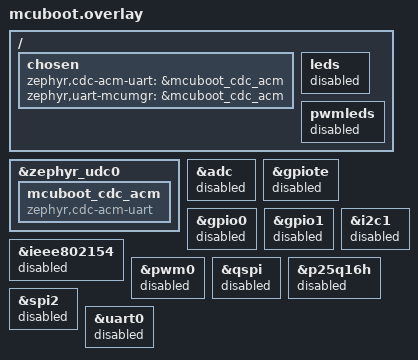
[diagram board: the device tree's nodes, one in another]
/*
 * MCUboot devicetree overlay (mcuboot sysbuild image).
 *
 * MCUboot's serial recovery runs over a USB CDC ACM UART, so a board whose
 * primary slot is empty or invalid can still be given an image over USB with
 * no SWD probe attached.
 *
 * The CDC ACM node is declared here rather than borrowed from the board. Board
 * DTS files name theirs inconsistently -- xiao_ble calls it usb_cdc_acm_uart,
 * the Adafruit nRF52840 boards call it cdc_acm_uart0 -- so referencing the
 * board's label would tie this file to one board. All this needs is
 * zephyr_udc0, which every nRF52840 has.
 */
/ {
    chosen {
        zephyr,cdc-acm-uart = &mcuboot_cdc_acm;
        zephyr,uart-mcumgr = &mcuboot_cdc_acm;
    };
};
&zephyr_udc0 {
    status = "okay";
    mcuboot_cdc_acm: mcuboot_cdc_acm {
        compatible = "zephyr,cdc-acm-uart";
    };
};

/*
 * LOCAL DEVIATION -- do not carry this to the upstream branch.
 *
 * Everything below is xiao_ble-specific and exists only to keep the bootloader
 * inside a 48 KB partition (MCUBOOT_PARTITION_SIZE = 0xC000 in __init__.py),
 * which is the size already flashed on our boards. Upstream deliberately has no
 * disable list: it is what makes the overlay board-agnostic, and it pays for
 * that with a 64 KB partition. The two go together -- restoring 0x10000 without
 * dropping this list just wastes 16 KB of slot.
 *
 * A bootloader needs USB and flash. It does not need the radio, the analog
 * front end, the external QSPI part, or any of the pin peripherals: serial
 * recovery is entered by an invalid primary slot, not by a GPIO
 * (BOOT_SERIAL_ENTRANCE_GPIO=n).
 */
/ {
    leds {
        status = "disabled";
    };
    pwmleds {
        status = "disabled";
    };
};
&adc {
    status = "disabled";
};
&gpiote {
    status = "disabled";
};
&gpio0 {
    status = "disabled";
};
&gpio1 {
    status = "disabled";
};
&i2c1 {
    status = "disabled";
};
&ieee802154 {
    status = "disabled";
};
&pwm0 {
    status = "disabled";
};
&qspi {
    status = "disabled";
};
&p25q16h {
    status = "disabled";
};
&spi2 {
    status = "disabled";
};
&uart0 {
    status = "disabled";
};
